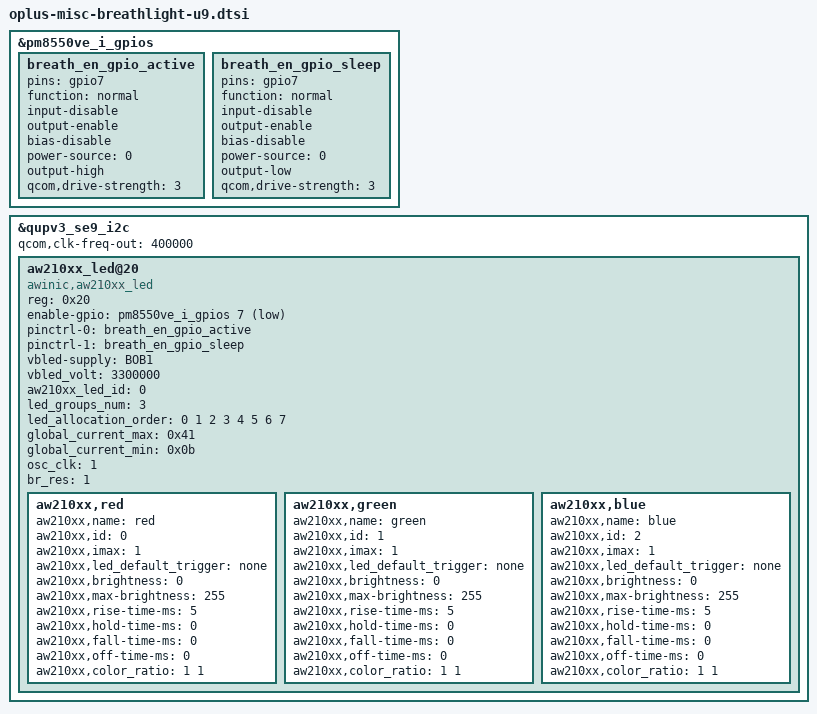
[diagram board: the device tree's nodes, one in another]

&pm8550ve_i_gpios {
	breath_en_gpio_active: breath_en_gpio_active {
		pins = "gpio7";
		function = "normal";
		input-disable;
		output-enable;
		bias-disable;
		power-source = <0>;
		output-high;
		qcom,drive-strength = <3>;
	};
	breath_en_gpio_sleep: breath_en_gpio_sleep {
		pins = "gpio7";
		function = "normal";
		input-disable;
		output-enable;
		bias-disable;
		power-source = <0>;
		output-low;
		qcom,drive-strength = <3>;
	};
};

&qupv3_se9_i2c {
	status = "ok";
	qcom,clk-freq-out = <400000>;

	aw210xx_led@20 {
		compatible = "awinic,aw210xx_led";
		reg = <0x20>;
		enable-gpio = <&pm8550ve_i_gpios 7 1>;
		pinctrl-names = "breath_en_gpio_active", "breath_en_gpio_sleep";
		pinctrl-0 = <&breath_en_gpio_active>;
		pinctrl-1 = <&breath_en_gpio_sleep>;
		vbled-supply = <&BOB1>;
		vbled_volt = <3300000>;

		aw210xx_led_id = <0>;
		led_groups_num = <3>;
		led_allocation_order = <0 1 2 3 4 5 6 7>;
		global_current_max = <0x41>;
		global_current_min = <0x0b>;
		osc_clk = <1>;
		br_res = <1>;
		status = "okay";

		aw210xx,red {
			aw210xx,name = "red";
			aw210xx,id = <0>;
			aw210xx,imax = <1>;
			aw210xx,led_default_trigger = "none";
			aw210xx,brightness = <0>;
			aw210xx,max-brightness = <255>;
			aw210xx,rise-time-ms = <5>;
			aw210xx,hold-time-ms = <0>;
			aw210xx,fall-time-ms = <0>;
			aw210xx,off-time-ms = <0>;
			aw210xx,color_ratio = <1 1>;
		};
		aw210xx,green {
			aw210xx,name = "green";
			aw210xx,id = <1>;
			aw210xx,imax = <1>;
			aw210xx,led_default_trigger = "none";
			aw210xx,brightness = <0>;
			aw210xx,max-brightness = <255>;
			aw210xx,rise-time-ms = <5>;
			aw210xx,hold-time-ms = <0>;
			aw210xx,fall-time-ms = <0>;
			aw210xx,off-time-ms = <0>;
			aw210xx,color_ratio = <1 1>;
		};
		aw210xx,blue {
			aw210xx,name = "blue";
			aw210xx,id = <2>;
			aw210xx,imax = <1>;
			aw210xx,led_default_trigger = "none";
			aw210xx,brightness = <0>;
			aw210xx,max-brightness = <255>;
			aw210xx,rise-time-ms = <5>;
			aw210xx,hold-time-ms = <0>;
			aw210xx,fall-time-ms = <0>;
			aw210xx,off-time-ms = <0>;
			aw210xx,color_ratio = <1 1>;
		};
	};
};
